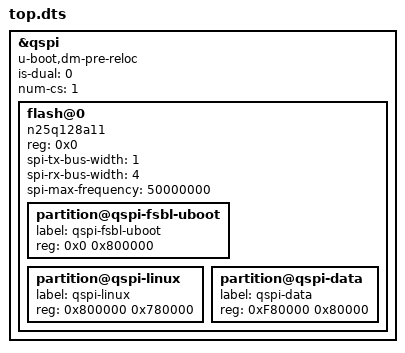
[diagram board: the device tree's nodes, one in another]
/include/ "system-top.dts"

&qspi {
 u-boot,dm-pre-reloc;
 status = "okay";
 is-dual = <0>;
 num-cs = <1>;
 flash@0 {
  compatible = "n25q128a11";
  reg = <0x0>;
  spi-tx-bus-width = <1>;
  spi-rx-bus-width = <4>;
  spi-max-frequency = <50000000>;
  #address-cells = <1>;
  #size-cells = <1>;
  partition@qspi-fsbl-uboot {
   label = "qspi-fsbl-uboot";
   reg = <0x0 0x800000>;
  };
  partition@qspi-linux {
   label = "qspi-linux";
   reg = <0x800000 0x780000>;
  };
  partition@qspi-data {
   label = "qspi-data";
   reg = <0xF80000 0x80000>;
  };
 };
};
